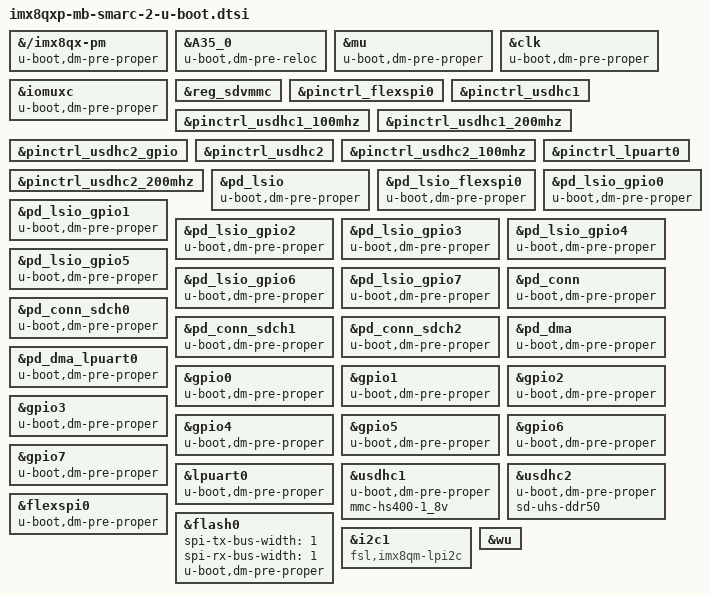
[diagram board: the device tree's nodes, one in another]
// SPDX-License-Identifier: GPL-2.0-or-later OR MIT
/*
 * Copyright 2018 - 2020 TQ-Systems GmbH
 */

&{/imx8qx-pm} {
	u-boot,dm-pre-proper;
	u-boot,dm-spl;
};

&A35_0 {
	u-boot,dm-pre-reloc;
};

&mu {
	u-boot,dm-pre-proper;
	u-boot,dm-spl;
};

&clk {
	u-boot,dm-pre-proper;
	u-boot,dm-spl;
};

&iomuxc {
	u-boot,dm-pre-proper;
	u-boot,dm-spl;
};

&reg_sdvmmc {
	u-boot,dm-spl;
};

&pinctrl_flexspi0 {
	u-boot,dm-spl;
};

&pinctrl_usdhc1 {
	u-boot,dm-spl;
};

&pinctrl_usdhc1_100mhz {
	u-boot,dm-spl;
};

&pinctrl_usdhc1_200mhz {
	u-boot,dm-spl;
};

&pinctrl_usdhc2_gpio {
	u-boot,dm-spl;
};

&pinctrl_usdhc2 {
	u-boot,dm-spl;
};

&pinctrl_usdhc2_100mhz {
	u-boot,dm-spl;
};

&pinctrl_usdhc2_200mhz {
	u-boot,dm-spl;
};

&pinctrl_lpuart0 {
	u-boot,dm-spl;
};

&pd_lsio {
	u-boot,dm-pre-proper;
	u-boot,dm-spl;
};

&pd_lsio_flexspi0 {
	u-boot,dm-pre-proper;
	u-boot,dm-spl;
};

&pd_lsio_gpio0 {
	u-boot,dm-pre-proper;
	u-boot,dm-spl;
};

&pd_lsio_gpio1 {
	u-boot,dm-pre-proper;
	u-boot,dm-spl;
};

&pd_lsio_gpio2 {
	u-boot,dm-pre-proper;
	u-boot,dm-spl;
};

&pd_lsio_gpio3 {
	u-boot,dm-pre-proper;
	u-boot,dm-spl;
};

&pd_lsio_gpio4 {
	u-boot,dm-pre-proper;
	u-boot,dm-spl;
};

&pd_lsio_gpio5 {
	u-boot,dm-pre-proper;
	u-boot,dm-spl;
};

&pd_lsio_gpio6 {
	u-boot,dm-pre-proper;
	u-boot,dm-spl;
};

&pd_lsio_gpio7 {
	u-boot,dm-pre-proper;
	u-boot,dm-spl;
};

&pd_conn {
	u-boot,dm-pre-proper;
	u-boot,dm-spl;
};

&pd_conn_sdch0 {
	u-boot,dm-pre-proper;
	u-boot,dm-spl;
};

&pd_conn_sdch1 {
	u-boot,dm-pre-proper;
	u-boot,dm-spl;
};

&pd_conn_sdch2 {
	u-boot,dm-pre-proper;
	u-boot,dm-spl;
};

&pd_dma {
	u-boot,dm-pre-proper;
	u-boot,dm-spl;
};

&pd_dma_lpuart0 {
	u-boot,dm-pre-proper;
};

&gpio0 {
	u-boot,dm-pre-proper;
	u-boot,dm-spl;
};

&gpio1 {
	u-boot,dm-pre-proper;
	u-boot,dm-spl;
};

&gpio2 {
	u-boot,dm-pre-proper;
	u-boot,dm-spl;
};

&gpio3 {
	u-boot,dm-pre-proper;
	u-boot,dm-spl;
};

&gpio4 {
	u-boot,dm-pre-proper;
	u-boot,dm-spl;
};

&gpio5 {
	u-boot,dm-pre-proper;
	u-boot,dm-spl;
};

&gpio6 {
	u-boot,dm-pre-proper;
	u-boot,dm-spl;
};

&gpio7 {
	u-boot,dm-pre-proper;
	u-boot,dm-spl;
};

&lpuart0 {
	u-boot,dm-pre-proper;
	u-boot,dm-spl;
};

&usdhc1 {
	u-boot,dm-spl;
	u-boot,dm-pre-proper;
	mmc-hs400-1_8v;
};

&usdhc2 {
	u-boot,dm-spl;
	u-boot,dm-pre-proper;
	sd-uhs-ddr50;
};

&flexspi0 {
	u-boot,dm-spl;
	u-boot,dm-pre-proper;
};

&flash0 {
	spi-tx-bus-width = <1>;
	spi-rx-bus-width = <1>;
	u-boot,dm-spl;
	u-boot,dm-pre-proper;
};

&i2c1 {
	compatible = "fsl,imx8qm-lpi2c", "fsl,imx-virt-i2c";
};

&wu {
	u-boot,dm-spl;
};
